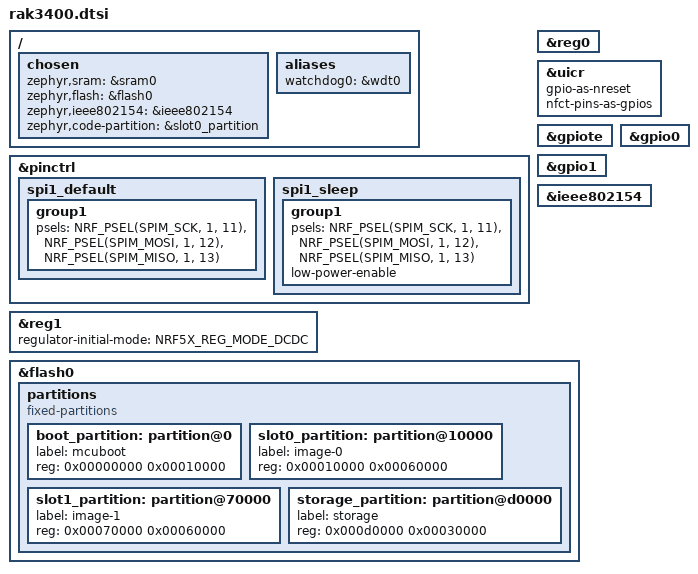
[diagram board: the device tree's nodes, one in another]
/*
 * SPDX-License-Identifier: Apache-2.0
 * Copyright (c) 2026 RAKwireless Technology Limited
 *
 * RAK3400 pinout description
 * P1    - VBUS
 * P2    - USB_D-
 * P3    - USB_D+
 * P4    - P0.13/I2C1_SDA
 * P5    - P0.14/I2C1_SCL
 * P6    - P0.15/UART2_RX
 * P7    - P0.16/UART2_TX
 * P8    - P0.17/UART2_DE
 * P9    - P0.19/UART1_RX
 * P10   - P0.20/UART1_TX
 * P11   - P0.21/UART1_DE
 * P12   - NFC2
 * P13   - NFC1
 *
 * P14   - GND
 * P15   - RF_BT
 * P16   - GND
 * P17   - RESET
 * P18   - SWDCLK
 * P19   - SWDIO
 * P20   - VBAT_SX
 * P21   - VBAT_IO_SX
 * P22   - GND
 *
 * P23   - P0.24/I2C2_SDA
 * P24   - P0.25/I2C2_SCL
 * P25   - P1.01
 * P26   - P1.02
 * P27   - P0.03
 * P28   - P0.04
 * P29   - P0.03/SPI_CLK
 * P30   - P0.02/SPI_DIO3
 * P31   - P0.28/SPI_DIO2
 * P32   - P0.29/SPI_DIO1
 * P33   - P0.30/SPI_DIO0
 * P34   - P0.26/SPI_CS
 * P35   - GND
 *
 * P36   - GND
 * P37   - RF_LoRa
 * P38   - GND
 * P39   - P0.31/AIN7
 * P40   - P0.05/AIN3
 * P41   - P0.04/AIN2
 * P42   - GND
 * P43   - VDD_NRF
 * P44   - VBAT_NRF
 */

#include <nordic/nrf52840_qiaa.dtsi>
#include <zephyr/dt-bindings/pinctrl/nrf-pinctrl.h>

&pinctrl {
	spi1_default: spi1_default {
		group1 {
			psels = <NRF_PSEL(SPIM_SCK, 1, 11)>,
				<NRF_PSEL(SPIM_MOSI, 1, 12)>,
				<NRF_PSEL(SPIM_MISO, 1, 13)>;
		};
	};

	spi1_sleep: spi1_sleep {
		group1 {
			psels = <NRF_PSEL(SPIM_SCK, 1, 11)>,
				<NRF_PSEL(SPIM_MOSI, 1, 12)>,
				<NRF_PSEL(SPIM_MISO, 1, 13)>;
			low-power-enable;
		};
	};
};

/ {
	chosen {
		zephyr,sram = &sram0;
		zephyr,flash = &flash0;
		zephyr,ieee802154 = &ieee802154;
		zephyr,code-partition = &slot0_partition;
	};

	aliases {
		watchdog0 = &wdt0;
	};
};

&reg0 {
	status = "okay";
};

&reg1 {
	regulator-initial-mode = <NRF5X_REG_MODE_DCDC>;
};

&uicr {
	gpio-as-nreset;
	nfct-pins-as-gpios;
};

&gpiote {
	status = "okay";
};

&gpio0 {
	status = "okay";
};

&gpio1 {
	status = "okay";
};

&ieee802154 {
	status = "okay";
};

&flash0 {
	status = "okay";

	partitions {
		compatible = "fixed-partitions";
		#address-cells = <1>;
		#size-cells = <1>;

		boot_partition: partition@0 {
			label = "mcuboot";
			reg = <0x00000000 0x00010000>;
		};

		slot0_partition: partition@10000 {
			label = "image-0";
			reg = <0x00010000 0x00060000>;
		};

		slot1_partition: partition@70000 {
			label = "image-1";
			reg = <0x00070000 0x00060000>;
		};

		storage_partition: partition@d0000 {
			label = "storage";
			reg = <0x000d0000 0x00030000>;
		};
	};
};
